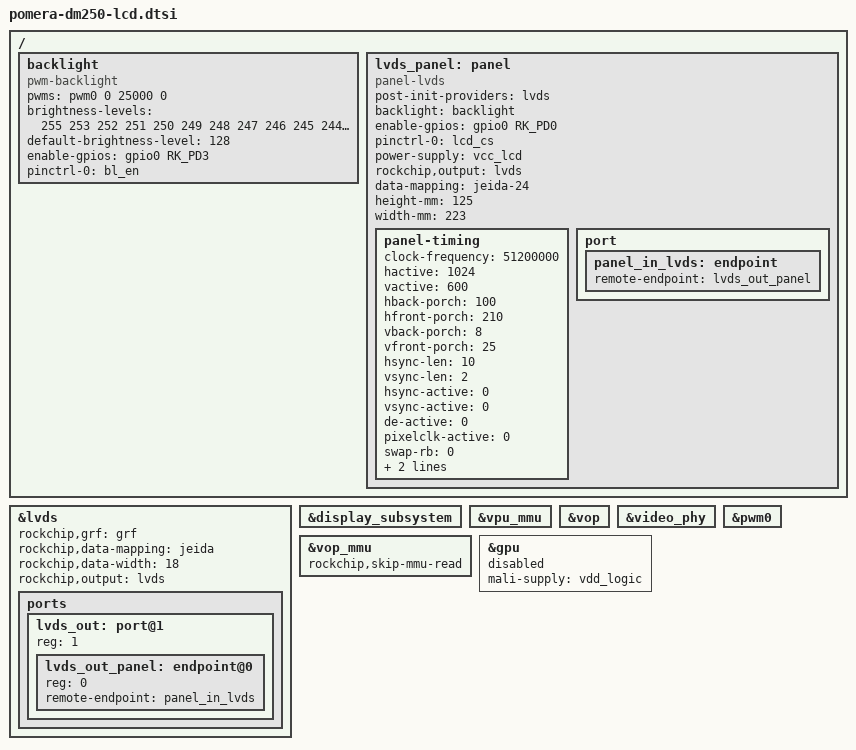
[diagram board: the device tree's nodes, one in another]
// SPDX-License-Identifier: (GPL-2.0+ OR MIT)

/ {
	backlight: backlight {
                compatible = "pwm-backlight";
                pwms = <&pwm0 0 25000 0>;
                brightness-levels = <
			255 253 252 251 250 249 248 247 246 245 244 243 242 241 240
			239 238 237 236 235 234 233 232 231 230 229 228 227 226 225
			224 223 222 221 220 219 218 217 216 215 214 213 212 211 210
			209 208 207 206 205 204 203 202 201 200 199 198 197 196 195
			194 193 192 191 190 189 188 187 186 185 184 183 182 181 180
			179 178 177 176 175 174 173 172 171 170 169 168 167 166 165
			164 163 162 161 160 159 158 157 156 155 154 153 152 151 150
			149 148 147 146 145 144 143 142 141 140 139 138 137 136 135
			134 133 132 131 130 129 128 127 126 125 124 123 122 121 120
			119 118 117 116 115 114 113 112 111 110 109 108 107 106 105
			104 103 102 101 100 99 98 97 96 95 94 93 92 91 90 89 88 87
			86 85 84 83 82 81 80 79 78 77 76 75 74 73 72 71 70 69 68 67
			66 65 64 63 62 61 60 59 58 57 56 55 54 53 52 51 50 49 48 47
			46 45 44 43 42 41 40 39 38 37 36 35 34 33 32 31 30 29 28 27
			26 25 24 23 22 21 20 19 18 17 16 15 14 13 12 11 10 9 8 7 6
			5 4 3 2 1 0>;
                default-brightness-level = <128>;
                enable-gpios = <&gpio0 RK_PD3 GPIO_ACTIVE_HIGH>;
		pinctrl-names = "default";
		pinctrl-0 = <&bl_en>;
                status = "okay";
        };

	lvds_panel: panel {
		compatible = "panel-lvds";
		status = "okay";
		post-init-providers = <&lvds>;
		backlight = <&backlight>;
		enable-gpios = <&gpio0 RK_PD0 GPIO_ACTIVE_HIGH>;
		pinctrl-names = "default";
		pinctrl-0 = <&lcd_cs>;
		power-supply = <&vcc_lcd>;
		rockchip,output = "lvds";
		data-mapping = "jeida-24";
		height-mm = <125>;
		width-mm = <223>;
		
		panel-timing {
			clock-frequency = <51200000>;
			hactive = <1024>;
			vactive = <600>;
			hback-porch = <100>;
			hfront-porch = <210>;
			vback-porch = <8>;
			vfront-porch = <25>;
			hsync-len = <10>;
			vsync-len = <2>;
			hsync-active = <0>;
			vsync-active = <0>;
			de-active = <0>;
			pixelclk-active = <0>;
			swap-rb = <0>;
			swap-rg = <0>;
			swap-gb = <0>;
		};

		port {
			panel_in_lvds: endpoint {
				remote-endpoint = <&lvds_out_panel>;
			};
		};
	};
};

&lvds {
	rockchip,grf = <&grf>;
        rockchip,data-mapping = "jeida";
        rockchip,data-width = <18>;
        rockchip,output = "lvds";
        status = "okay";

        ports {
		lvds_out: port@1 {
                        reg = <1>;
                        #address-cells = <1>;
                        #size-cells = <0>;

                        lvds_out_panel: endpoint@0 {
				reg = <0>;
				remote-endpoint = <&panel_in_lvds>;
                        };
                };
        };
};

&display_subsystem {
	status = "okay";
};

&vpu_mmu {
	status = "okay";
};


&vop {
	status = "okay";
};

&video_phy {
	status = "okay";
};

&vop_mmu {
	rockchip,skip-mmu-read;
};

&vpu_mmu {
	status = "okay";
};

&vpu_mmu {
	status = "okay";
};

/* not works yet */
&gpu {
	status = "disabled";
	/* status = "okay"; */
	mali-supply = <&vdd_logic>;
	/* memory-region = <&display_pool>; */
};

&pwm0 {
	status = "okay";
};
